# rCSL_uart_001 register map
Vendor: Texas Instruments
Peripheral module from a debugger description file (folder OMAPL138_C6748).
Registers are 32-bit, access not given, reset 0x0 unless marked. A register's access mark holds for its fields unless they carry their own. Offsets are as the file gives them; lines under a group give offsets from that group; [hi:lo] are bit positions; {n}, {i} and the like mark numbered series; 'fields as' and 'values as' point back to an identical list; <NAME> marks a mode.

## UART — Universal Asynchronous Receive Transmit
0x00 RBR — Receiver Buffer Register
  [7:0] DATA ro — Received data
0x00 THR — Transmitter Holding Register
  [7:0] DATA wo — Data to transmit
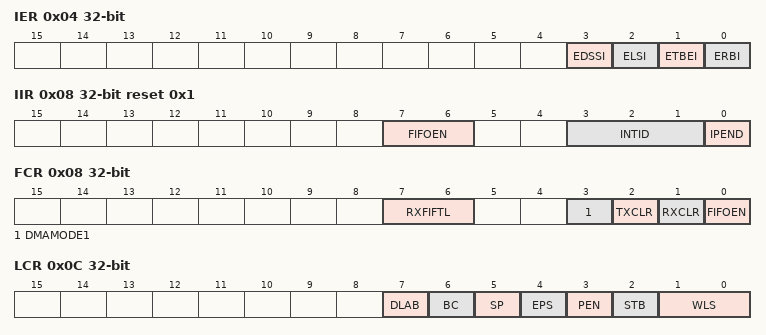
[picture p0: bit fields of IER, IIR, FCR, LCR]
0x04 IER — The interrupt enable register (IER) is used to individually enable or disable each type of interrupt request that can be generated by the UART. Each interrupt request that is enabled in IER is forwarded to the CPU.
  [3] EDSSI rw — Enable Modem Status Interrupt
    0=DISABLE; 1=ENABLE
  [2] ELSI rw — Receiver line status interrupt enable.
    0=DISABLE (Receiver line status interrupt is disabled.); 1=ENABLE (Receiver line status interrupt is enabled.)
  [1] ETBEI rw — Transmitter holding register empty interrupt enable.
    0=DISABLE (Transmitter holding register empty interrupt is disabled.); 1=ENABLE (Transmitter holding register empty interrupt is enabled.)
  [0] ERBI rw — Receiver data available interrupt and character timeout indication interrupt enable.
    0=DISABLE (Receiver data available interrupt and character timeout indication interrupt is disabled.); 1=ENABLE (Receiver data available interrupt and character timeout indication interrupt is enabled.)
0x08 IIR reset 0x1 — The interrupt identification register (IIR) is a read-only register at the same address as the FIFO control register (FCR), which is a write-only register. When an interrupt is generated and enabled in the interrupt enable register (IER), IIR indicates that an interrupt is pending in the IPEND bit and encodes the type of interrupt in the INTID bits.
  [7:6] FIFOEN ro — FIFOs Enabled Always 00b in Non-FIFO mode Set to 11b when bit 0 of the FCR register is set
  [3:1] INTID ro — Encodes the different types of interrupt
    0=MODSTAT (Modem Status (Priority 4) Lowest); 1=THRE (THR Empty (Priority 3)); 2=RDA (Received Data Available (Priority 2)); 3=RLS (Receiver Line Status (Priority 1) Highest); 6=CTI (Character Timeout Indication (Priority 2))
  [0] IPEND ro — Interrupt Pending This bit is used either in a hardwire prioritized (nirq) or polled interrupt system
    0=PEND (No interrupts pending); 1=NO_PEND
0x08 FCR — The FIFO control register (FCR) is a write-only register at the same address as the interrupt identification register (IIR), which is a read-only register. Use FCR to enable and clear the FIFOs and to select the receiver FIFO trigger level.The FIFOEN bit must be set to 1 before other FCR bits are written to or the FCR bits are not programmed.
  [7:6] RXFIFTL wo — 0-3h Receiver FIFO trigger level. RXFIFTL sets the trigger level for the receiver FIFO. When the trigger level is reached, a receiver data-ready interrupt is generated (if the interrupt request is enabled). Once the FIFO drops below the trigger level, the interrupt is cleared.
    0=CHAR1 (1 byte); 1=CHAR4 (4 byte); 2=CHAR8 (8 byte); 3=CHAR14 (14 byte)
  [3] DMAMODE1 wo — DMA MODE1 enable if FIFOs are enabled. Always write 1 to DMAMODE1. After a hardware reset, change DMAMODE1 from 0 to 1. DMAMOD1 = 1 is a requirement for proper communication between the UART and the EDMA controller.
    0=DISABLE (DMA MODE1 is disabled.); 1=ENABLE (DMA MODE1 is enabled.)
  [2] TXCLR wo — Transmitter FIFO clear. Write a 1 to TXCLR to clear the bit.
    1=CLR (Clears transmitter FIFO and resets the transmitter FIFO counter. The shift register is not cleared.)
  [1] RXCLR wo — Receiver FIFO clear. Write a 1 to RXCLR to clear the bit.
    1=CLR (Clears receiver FIFO and resets the receiver FIFO counter. The shift register is not cleared.)
  [0] FIFOEN wo — Transmitter and receiver FIFOs mode enable. FIFOEN must be set before other FCR bits are written to or the FCR bits are not programmed. Clearing this bit clears the FIFO counters.
    0=DISABLE (Non-FIFO mode. The transmitter and receiver FIFOs are disabled, and the FIFO pointers are cleared.); 1=ENABLE (FIFO mode. The transmitter and receiver FIFOs are enabled.)
0x0C LCR — The system programmer controls the format of the asynchronous data communication exchange by using LCR. In addition, the programmer can retrieve, inspect, and modify the content of LCR; this eliminates the need for separate storage of the line characteristics in system memory.
  [7] DLAB rw — Divisor latch access bit. The divisor latch registers (DLL and DLH) can be accessed at dedicated addresses or at addresses shared by RBR, THR, and IER. Using the shared addresses requires toggling DLAB to change which registers are selected. If you use the dedicated addresses, you can keep DLAB = 0.
    0=DISABLE (Allows access to the receiver buffer register (RBR), the transmitter holding register (THR), and the interrupt enable register (IER) selected. At the address shared by RBR, THR, and DLL, the CPU can read from RBR and write to THR. At the address shared by IER and DLH, the CPU can read from and write to IER.); 1=ENABLE (Allows access to the divisor latches of the baud generator during a read or write operation (DLL and DLH). At the address shared by RBR, THR, and DLL, the CPU can read from and write to DLL. At the address shared by IER and DLH, the CPU can read from and write to DLH.)
  [6] BC rw — Break control.
    0=DISABLE (Break condition is disabled); 1=ENABLE (Break condition is transmitted to the receiving UART. A break condition is a condition where the UART_TX signal is forced to the spacing (cleared) state.)
  [5] SP rw — Stick parity. The SP bit works in conjunction with the EPS and PEN bits.
    0=DISABLE (Stick parity is disabled); 1=ENABLE (Stick parity is enabled. When odd parity is selected (EPS = 0), the PARITY bit is transmitted and checked as set. When even parity is selected (EPS = 1), the PARITY bit is transmitted and checked as cleared.)
  [4] EPS rw — Even parity select. Selects the parity when parity is enabled (PEN = 1). The EPS bit works in conjunction with the SP and PEN bits.
    0=ODD (Odd parity is selected (an odd number of logic 1s is transmitted or checked in the data and PARITY bits).); 1=EVEN (Even parity is selected (an even number of logic 1s is transmitted or checked in the data and PARITY bits).)
  [3] PEN rw — Parity Enable .The PEN bit works in conjunction with the SP and EPS bits.
    0=DISABLE (no parity bit is transmitted or checked); 1=ENABLE (A parity bit is generated in transmitted data and is checked in received data between the last data word bit and the first stop bit)
  [2] STB rw — Number of Stop Bits Generated This bit specifies either one, one and a half, or two stop bits in each transmitted character. This bit is combined with the word length bits (LCR[1] and LCR[0]) determine the number of stop bits. The receiver clocks only the first stop bit regardless of the number of stop bits selected -------------------------------------------------------------------------------------------- Bit 2 Word Length Number of Stop Bits Generated -------------------------------------------------------------------------------------------- 0 Any word length 1 1 5 bits 1.5 1 6 bits 2 1 7 bits 2 1 8 bits 2
    0=1BIT; 1=WLS
  [1:0] WLS rw — Word length select. Number of bits in each transmitted or received serial character. When STB = 1, the WLS bit determines the number of STOP bits.
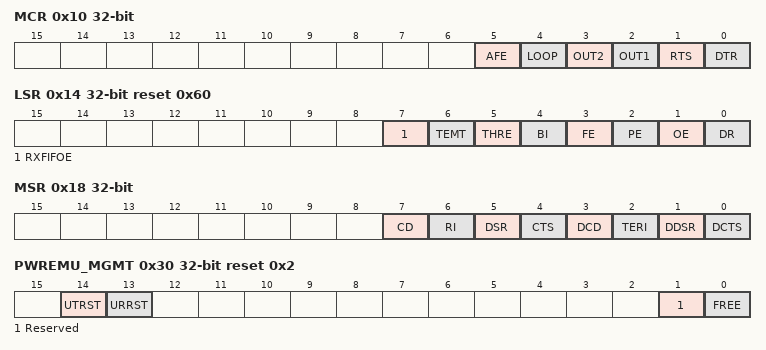
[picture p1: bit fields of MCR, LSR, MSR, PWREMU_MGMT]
0x10 MCR — The modem control register provides the ability to enable/disable the autoflow functions, and enable/disable the loopback function for diagnostic purposes.
  [5] AFE rw — Autoflow control enable. Autoflow control allows the RTS and CTS signals to provide handshaking between UARTs during data transfer. When AFE = 1, the RTS bit determines the autoflow control enabled. ---------------------------------------------------------------------- Bit 5 Bit 1 Autoflow Control Configuration ---------------------------------------------------------------------- 1 1 Auto-rts and auto-cts enabled 1 0 Auto-cts only enabled 0 X Auto-rts and auto-cts disabled
    0=DISABLE (Autoflow control is disabled); 1=ENABLE (Autoflow control is enabled)
  [4] LOOP rw — Loop back mode enable. LOOP is used for the diagnostic testing using the loop back feature.
    0=DISABLE (Disable loop back mode); 1=ENABLE (Loop back mode is enabled. When LOOP is set, the following occur: The UART_TX signal is set high. The UART_RX pin is disconnected. The output of the transmitter shift register (TSR) is lopped back in to the receiver shift register (RSR) input.)
  [3] OUT2 ro
    0=DISABLE; 1=ENABLE
  [2] OUT1 ro
    0=DISABLE; 1=ENABLE
  [1] RTS rw — RTS control. When AFE = 1, the RTS bit determines the autoflow control enabled. Note that all UARTs do not support this feature, see the device-specific data manual for supported features. If this feature is not available, this bit is reserved and should be cleared to 0. 0 RTS is disabled, CTS is only enabled. 1 RTS and CTS are enabled.
    0=HIGH (The associated output is forced high); 0=DISABLE (Auto-rts is disabled); 1=ENABLE (Auto-rts is enabled); 1=LOW (The associated output is forced low)
  [0] DTR rw
    0=DISABLE; 1=ENABLE
0x14 LSR reset 0x60 — LSR provides information to the CPU concerning the status of data transfers. LSR is intended for read operations only; do not write to this register. Bits 1 through 4 record the error conditions that produce a receiver line status interrupt.
  [7] RXFIFOE ro — Receiver FIFO error.
    0=NOERROR (In non-FIFO mode: There has been no error, or RXFIFOE was cleared because the CPU read the erroneous character from the receiver buffer register (RBR). In FIFO mode: There has been no error, or RXFIFOE was cleared because the CPU read the erroneous character from the receiver FIFO and there are no more errors in the receiver FIFO.); 1=ERROR (In non-FIFO mode: There is a parity error, framing error, or break indicator in the receiver buffer register (RBR). In FIFO mode: At least one parity error, framing error, or break indicator in the receiver FIFO.)
  [6] TEMT ro — Transmitter empty (TEMT) indicator.
    0=FULL (In non-FIFO mode: Either the transmitter holding register (THR) or the transmitter shift register (TSR) contains a data character. In FIFO mode: Either the transmitter FIFO or the transmitter shift register (TSR) contains a data character.); 1=EMPTY (In non-FIFO mode: Both the transmitter holding register (THR) and the transmitter shift register (TSR) are empty. In FIFO mode: Both the transmitter FIFO and the transmitter shift register (TSR) are empty.)
  [5] THRE ro — Transmitter holding register empty (THRE) indicator. If the THRE bit is set and the corresponding interrupt enable bit is set (ETBEI = 1 in IER), an interrupt request is generated.
    0=FULL (In non-FIFO mode: Transmitter holding register (THR) is not empty. THR has been loaded by the CPU. In FIFO mode: Transmitter FIFO is not empty. At least one character has been written to the transmitter FIFO. You can write to the transmitter FIFO if it is not full.); 1=EMPTY (In non-FIFO mode: Transmitter holding register (THR) is empty (ready to accept a new character). The content of THR has been transferred to the transmitter shift register (TSR). In FIFO mode:Transmitter FIFO is empty. The last character in the FIFO has been transferred to the transmitter shift register (TSR).)
  [4] BI ro — Break indicator. The BI bit is set whenever the receive data input (RX) was held low for longer than a full-word transmission time. A full-word transmission time is defined as the total time to transmit the START, data, PARITY, and STOP bits. If the BI bit is set and the corresponding interrupt enable bit is set (ELSI = 1 in IER), an interrupt request is generated.
    0=NOBREAK (In non-FIFO mode: No break has been detected, or the BI bit was cleared because the CPU read the erroneous character from the receiver buffer register (RBR). In FIFO mode: No break has been detected, or the BI bit was cleared because the CPU read the erroneous character from the receiver FIFO and the next character to be read from the FIFO has no break indicator.); 1=BREAK (In non-FIFO mode: A break has been detected with the character in the receiver buffer register (RBR). In FIFO mode: A break has been detected with the character at the top of the receiver FIFO.)
  [3] FE ro — Framing error (FE) indicator. A framing error occurs when the received character does not have a valid STOP bit. In response to a framing error, the UART sets the FE bit and waits until the signal on the RX pin goes high. Once the RX signal goes high, the receiver is ready to detect a new START bit and receive new data. If the FE bit is set and the corresponding interrupt enable bit is set (ELSI = 1 in IER), an interrupt request is generated.
    0=NOERROR (In non-FIFO mode: No framing error has been detected, or the FE bit was cleared because the CPU read the erroneous data from the receiver buffer register (RBR). In FIFO mode: No framing error has been detected, or the FE bit was cleared because the CPU read the erroneous data from the receiver FIFO and the next character to be read from the FIFO has no framing error.); 1=ERROR (In non-FIFO mode: A framing error has been detected with the character in the receiver buffer register (RBR). In FIFO mode:A framing error has been detected with the character at the top of the receiver FIFO.)
  [2] PE ro — Parity error (PE) indicator. A parity error occurs when the parity of the received character does not match the parity selected with the EPS bit in the line control register (LCR). If the PE bit is set and the corresponding interrupt enable bit is set (ELSI = 1 in IER), an interrupt request is generated.
    0=NOERROR (In non-FIFO mode: No parity error has been detected, or the PE bit was cleared because the CPU read the erroneous data from the receiver buffer register (RBR). In FIFO mode: No parity error has been detected, or the PE bit was cleared because the CPU read the erroneous data from the receiver FIFO and the next character to be read from the FIFO has no parity error.); 1=ERROR (In non-FIFO mode:A parity error has been detected with the character in the receiver buffer register (RBR). In FIFO mode: A parity error has been detected with the character at the top of the receiver FIFO.)
  [1] OE ro — Overrun error (OE) indicator An overrun error in the non-FIFO mode is different from an overrun error in the FIFO mode. If the OE bit is set and the corresponding interrupt enable bit is set (ELSI = 1 in IER), an interrupt request is generated.
    0=NOERROR (In non-FIFO mode:No overrun error has been detected, or the OE bit was cleared because the CPU read the content of the line status register (LSR). In FIFO mode:No overrun error has been detected, or the OE bit was cleared because the CPU read the content of the line status register (LSR).); 1=ERROR (In non-FIFO mode:Overrun error has been detected. Before the character in the receiver buffer register (RBR) could be read, it was overwritten by the next character arriving in RBR. In FIFO mode: Overrun error has been detected. If data continues to fill the FIFO beyond the trigger level, an overrun error occurs only after the FIFO is full and the next character has been completely received in the shift register. An overrun error is indicated to the CPU as soon as it happens. The new character overwrites the character in the shift register, but it is not transferred to the FIFO.)
  [0] DR ro — Data-ready (DR) indicator for the receiver. If the DR bit is set and the corresponding interrupt enable bit is set (ERBI = 1 in IER), an interrupt request is generated.
    0=NOTREADY (In non-FIFO mode:Data is not ready, or the DR bit was cleared because the character was read from the receiver buffer register (RBR). In FIFO mode: Data is not ready, or the DR bit was cleared because all of the characters in the receiver FIFO have been read.); 1=READY (In non-FIFO mode: Data is ready. A complete incoming character has been received and transferred into the receiver buffer register (RBR). In FIFO mode:Data is ready. There is at least one unread character in the receiver FIFO. If the FIFO is empty, the DR bit is set as soon as a complete incoming character has been received and transferred into the FIFO. The DR bit remains set until the FIFO is empty again.)
0x18 MSR — Modem Status Register
  [7] CD ro — Complement of the Carrier Detect input When the UART is in the diagnostic test mode (loopback mode MCR[4] = 1), this bit is equal to the MCR bit 3 (OUT2)
    0=NOCD; 1=CD
  [6] RI ro — Complement of the Ring Indicator input When the UART is in the diagnostic test mode (loopback mode MCR[4] = 1), this bit is equal to the MCR bit 2 (OUT1)
    0=NORI; 1=RI
  [5] DSR ro — Complement of the Data Set Ready input When the UART is in the diagnostic test mode (loopback mode MCR[4] = 1), this bit is equal to the MCR bit 0 (DTR)
    0=NODSR; 1=DSR
  [4] CTS ro — Complement of the Clear To Send input When the UART is in the diagnostic test mode (loopback mode MCR[4] = 1), this bit is equal to the MCR bit 1 (RTS)
    0=NOCTS; 1=CTS
  [3] DCD ro — Change in DCD indicator bit DCD indicates that the DCD input has changed state since the last time it was read by the CPU. When DCD is set and the modem status interrupt is enabled, a modem status interrupt is generated
    0=NODCD; 1=DCD
  [2] TERI ro — Trailing edge of RI (TERI) indicator bit TERI indicates that the RI input has changed from a low to a high. When TERI is set and the modem status interrupt is enabled, a modem status interrupt is generated
    0=NOTERI; 1=TERI
  [1] DDSR ro — Change in DSR indicator bit DDSR indicates that the DSR input has changed state since the last time it was read by the CPU. When DDSR is set and the modem status interrupt is enabled, a modem status interrupt is generated
    0=NODDSR; 1=DDSR
  [0] DCTS ro — Change in CTS indicator bit DCTS indicates that the CTS input has changed state since the last time it was read by the CPU. When DCTS is set (autoflow control is not enabled and the modem status interrupt is enabled), a modem status interrupt is generated. When autoflow control is enabled, no interrupt is generated
    0=NODCTS; 1=DCTS
0x1C SCR — Scratch Pad Register
  [7:0] SCR rw — These bits are intended for the programmer's use as a scratch pad in the sense that it temporarily holds the programmer's data without affecting any other UART operation.
0x20 DLL — DLL holds the least-significant bits of the divisor.This divisor latch must be loaded during initialization of the UART in order to ensure desired operation of the baud generator.
  [7:0] DLL rw — The 8 least-significant bits (LSBs) of the 16-bit divisor for generation of the baud clock in the baud rate generator
0x24 DLH — DLH holds the most-significant bits of the divisor.This divisor latch must be loaded during initialization of the UART in order to ensure desired operation of the baud generator.
  [7:0] DLH rw — The 8 most-significant bits (MSBs) of the 16-bit divisor for generation of the baud clock in the baud rate generator
0x28 REVID1 ro reset 0x11020002 — The revision identification registers (REVD1) contain identification data for the peripheral.
  [31:0] REV — Peripheral Identification Number
0x2C REVID2 ro — Revision ID Register 2
  [31:0] REV — Peripheral Identification Number
0x30 PWREMU_MGMT reset 0x2 — Power Management and Emulation Register
  [14] UTRST rw — UART transmitter reset. Resets and enables the transmitter
    0=RESET (Transmitter is disabled and in reset state); 1=ENABLE (Transmitter is enabled)
  [13] URRST rw — UART receiver reset. Resets and enables the receiver
    0=RESET (Receiver is disabled and in reset state); 1=ENABLE (Receiver is enabled)
  [1] Reserved — This bit is always 1 . Writing this bit does not affect value (access N)
  [0] FREE rw — Free-running enable mode bit. This bit determines the emulation mode functionality of the UART. In suspended mode, the UART can handle register read/write requests, but does not generate any transmission/reception, interrupts or events.
    0=STOP (If a transmission is not in progress, the UART stops immediately. If a transmission is in progress, the UART stops after completion of the one word transmission); 1=RUN (Free-running mode is enabled; UART continues to run normally)
0x34 MDR — Mode Definition Register
  [0] OSM_SEL rw — Over-Sampling Select
    0=16xOVERSAMPLING; 1=13xOVERSAMPLING
